# HK32L0xx register map
Vendor: HKMicroChip Ltd.; Series: HK32L0xx; File version: 1.3
CPU: CM0 r0p0, little endian, no MPU, no FPU, 3 interrupt priority bits
Registers are 32-bit, read-write, reset 0x0 unless marked. A register's access mark holds for its fields unless they carry their own. Offsets are from the block's base; [hi:lo] are bit positions; {n}, {i} and the like mark numbered series.

## TIM1
Base 0x40012C00
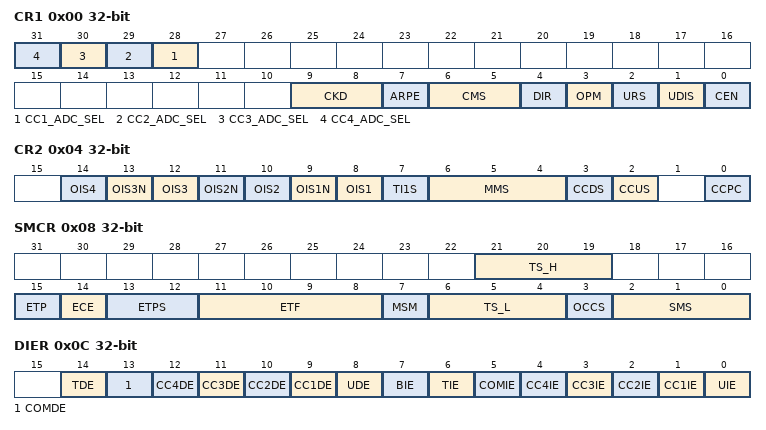
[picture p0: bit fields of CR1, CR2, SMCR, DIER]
0x00 CR1
  [n+27] CC{n}_ADC_SEL (n=1..4) — ADC trigger signal generation source
  [9:8] CKD — Clock division factor
  [7] ARPE — Auto-reload preload enable
  [6:5] CMS — Center-aligned mode selection
  [4] DIR — Direction
  [3] OPM — One pulse mode
  [2] URS — Update request source
  [1] UDIS — Update disable
  [0] CEN — Counter enable
0x04 CR2
  [2n+6] OIS{n} (n=1..4) — Output Idle state {n}
  [13] OIS3N — Output Idle state 3
  [11] OIS2N — Output Idle state 2
  [9] OIS1N — Output Idle state 1
  [7] TI1S — TI1 selection
  [6:4] MMS — Master mode selection
  [3] CCDS — Capture/Compare DMA selection
  [2] CCUS — Capture/Compare control update selection
  [0] CCPC — Capture/Compare preloaded control
0x08 SMCR
  [21:19] TS_H — Tigger selection
  [15] ETP — External trigger polarity
  [14] ECE — External clock enable
  [13:12] ETPS — External trigger prescaler
  [11:8] ETF — External trigger filter
  [7] MSM — Master/slave mode
  [6:4] TS_L — Trigger selection
  [3] OCCS — OCREF clear selection
  [2:0] SMS — Slave mode selection
0x0C DIER
  [14] TDE — Trigger DMA request enable
  [13] COMDE — COM DMA request enable
  [n+8] CC{n}DE (n=1..4) — Capture/Compare {n} DMA request enable
  [8] UDE — Update DMA request enable
  [7] BIE — Break interrupt enable
  [6] TIE — Trigger interrupt enable
  [5] COMIE — COM interrupt enable
  [n] CC{n}IE (n=1..4) — Capture/Compare {n} interrupt enable
  [0] UIE — Update interrupt enable
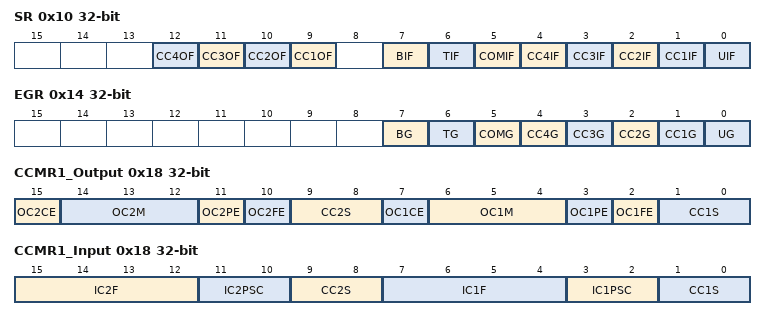
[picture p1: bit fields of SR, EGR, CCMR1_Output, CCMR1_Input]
0x10 SR
  [n+8] CC{n}OF (n=1..4) — Capture/Compare {n} overcapture flag
  [7] BIF — Break interrupt flag
  [6] TIF — Trigger interrupt flag
  [5] COMIF — COM interrupt flag
  [n] CC{n}IF (n=1..4) — Capture/Compare {n} interrupt flag
  [0] UIF — Update interrupt flag
0x14 EGR wo
  [7] BG — Break generation
  [6] TG — Trigger generation
  [5] COMG — Capture/Compare control update generation
  [n] CC{n}G (n=1..4) — Capture/Compare {n} generation
  [0] UG — Update generation
0x18 CCMR1_Output
  [15] OC2CE — Output Compare 2 clear enable
  [14:12] OC2M — Output Compare 2 mode
  [11] OC2PE — Output Compare 2 preload enable
  [10] OC2FE — Output Compare 2 fast enable
  [9:8] CC2S — Capture/Compare 2 selection
  [7] OC1CE — Output Compare 1 clear enable
  [6:4] OC1M — Output Compare 1 mode
  [3] OC1PE — Output Compare 1 preload enable
  [2] OC1FE — Output Compare 1 fast enable
  [1:0] CC1S — Capture/Compare 1 selection
0x18 CCMR1_Input (alternate view of CCMR1_Output)
  [15:12] IC2F — Input capture 2 filter
  [11:10] IC2PSC — Input capture 2 prescaler
  [9:8] CC2S — Capture/Compare 2 selection
  [7:4] IC1F — Input capture 1 filter
  [3:2] IC1PSC — Input capture 1 prescaler
  [1:0] CC1S — Capture/Compare 1 Selection
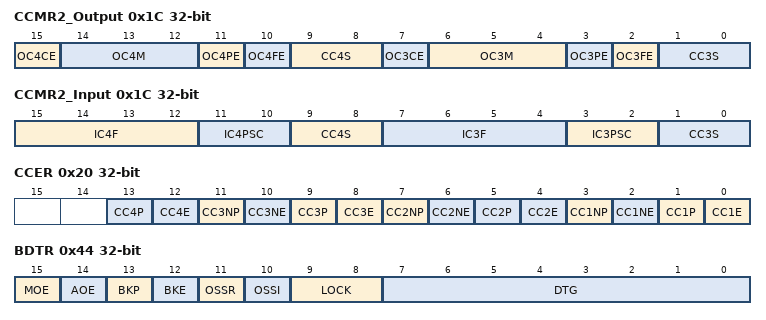
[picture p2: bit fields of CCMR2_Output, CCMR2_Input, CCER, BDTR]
0x1C CCMR2_Output
  [15] OC4CE — Output compare 4 clear enable
  [14:12] OC4M — Output compare 4 mode
  [11] OC4PE — Output compare 4 preload enable
  [10] OC4FE — Output compare 4 fast enable
  [9:8] CC4S — Capture/Compare 4 selection
  [7] OC3CE — Output compare 3 clear enable
  [6:4] OC3M — Output compare 3 mode
  [3] OC3PE — Output compare 3 preload enable
  [2] OC3FE — Output compare 3 fast enable
  [1:0] CC3S — Capture/Compare 3 selection
0x1C CCMR2_Input (alternate view of CCMR2_Output)
  [15:12] IC4F — Input capture 4 filter
  [11:10] IC4PSC — Input capture 4 prescaler
  [9:8] CC4S — Capture/Compare 4 selection
  [7:4] IC3F — Input capture 3 filter
  [3:2] IC3PSC — Input capture 3 prescaler
  [1:0] CC3S — Capture/Compare 3 selection
0x20 CCER
  [4n-3] CC{n}P (n=1..4) — Capture/Compare {n} output polarity
  [4n-4] CC{n}E (n=1..4) — Capture/Compare {n} output enable
  [11] CC3NP — Capture/Compare 3 complementary output polarity
  [10] CC3NE — Capture/Compare 3 complementary output enable
  [7] CC2NP — Capture/Compare 1 complementary output polarity
  [6] CC2NE — Capture/Compare 2 complementary output enable
  [3] CC1NP — Capture/Compare 1 complementary output polarity
  [2] CC1NE — Capture/Compare 1 complementary output enable
0x24 CNT
  [15:0] CNT — Counter value
0x28 PSC
  [15:0] PSC — Prescaler value
0x2C ARR reset 0xFFFF
  [15:0] ARR — Auto-reload value
0x30 RCR
  [7:0] REP — Repetition counter value
{0x30+4i} CCR{i} (i=1..4)
  [15:0] CCR{i} — Capture/Compare {i} value
0x44 BDTR
  [15] MOE — Main output enable
  [14] AOE — Automatic output enable
  [13] BKP — Break polarity
  [12] BKE — Break enable
  [11] OSSR — Off-state selection for Run mode
  [10] OSSI — Off-state selection for Idle mode
  [9:8] LOCK — Lock configuration
  [7:0] DTG — Dead-time generator setup
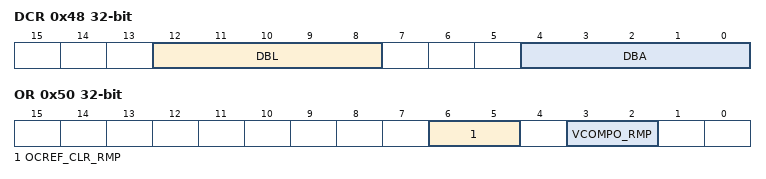
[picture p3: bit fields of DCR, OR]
0x48 DCR
  [12:8] DBL — DMA burst length
  [4:0] DBA — DMA base address
0x4C DMAR
  [15:0] DMAB — DMA register for burst accesses
0x50 OR
  [6:5] OCREF_CLR_RMP — Clear OCREF remap
  [3:2] VCOMPO_RMP — Voltage compare output remap
